# FM33L0XX register map
File version: 1.0
CPU: SC000 r1p0, little endian, no MPU, no FPU, 3 interrupt priority bits
Registers are 32-bit, read-write, reset 0x0 unless marked. A register's access mark holds for its fields unless they carry their own. Offsets are from the block's base; [hi:lo] are bit positions.

## U7816 — U7816 Registers
Base 0x40011C00
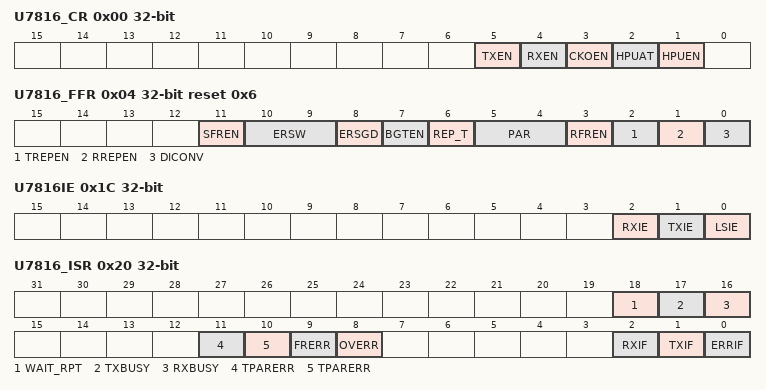
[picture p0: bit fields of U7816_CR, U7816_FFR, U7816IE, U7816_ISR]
0x00 U7816_CR — U7816 CONTROL REGISTER
  [5] TXEN — TX ENABLE
    0=TX_DIS (TX DISABLE); 1=TX_EN (TX ENABLE)
  [4] RXEN — RX ENABLE
    0=RX_DIS (RX DISABLE); 1=RX_EN (RX ENABLE)
  [3] CKOEN — CLK OUTPUT ENABLE
    0=CKO_DIS (CLK OUPUT DISABLE); 1=CKO_EN (CLK OUTPUT ENABLE)
  [2] HPUAT — AUTO PULLUP ENABLE
    0=DISABLE (AUTO PULLUP DISABLE); 1=ENABLE (AUTO PULLUP ENABLE)
  [1] HPUEN — PULLUP ENABLE
    0=DISABLE (PULLUP DISABLE); 1=ENABLE (PULLUP ENABLE)
0x04 U7816_FFR reset 0x6 — U7816 FRAME CONTROL
  [11] SFREN
    0=2 etu; 1=3 etu
  [10:9] ERSW — ERROR SIGNAL LENGTH
    0=2ETU; 1=2ETU; 2=1.5ETU; 3=1ETU
  [8] ERSGD — GUARDTIME LENGTH AFTER ERROR SIGNAL
    0=2.5ETU (2~2.5ETU); 1=1.5ETU (1~1.5ETU)
  [7] BGTEN — block guard time enable
    0=BGT_DIS (BGT DISABLE); 1=BGT_EN
  [6] REP_T — REPEAT TIME
    0=1T; 1=3T
  [5:4] PAR — PARITY MODE
    0=Even; 1=Odd; 2=Always1; 3=NOT_HANDLE
  [3] RFREN — Guard Time Length
    0=2ETU; 1=1ETU
  [2] TREPEN — AUTO POSTBACK WHEN RECEIVED ERROR SIGNAL
  [1] RREPEN — AUTO POSTBACK ERROR SIGNAL WHEN PARITY_ERR
  [0] DICONV — DIRECTION CONV
    0=LSB (LSB FIRST); 1=MSB (MSB FIRST)
0x08 U7816EGT — U7816 EGT config
  [7:0] TXEGT
0x0C U7816CLKDIV reset 0x3 — U7816 CLK DIVIDED CONFIG
  [4:0] CLKDIV — CLK DIVIDED F7816=FAPBCLK/(CLKDIV+1)
0x10 U7816_BGR reset 0x173 — U7816 FREQ DIVISION CONFIG
  [11:0] PDIV — Baud = F7816/(PDIV+1)
0x14 U7816_RXBUF
  [7:0] RXBUF
0x18 U7816_TXBUF
  [7:0] TXBUF
0x1C U7816IE
  [2] RXIE
  [1] TXIE
  [0] LSIE — FOR ERROR_FLAG
0x20 U7816_ISR — U7816 IF
  [18] WAIT_RPT
  [17] TXBUSY
  [16] RXBUSY
  [11] TPARERR — TX PARITY ERROR
  [10] TPARERR — TX PARITY ERROR
  [9] FRERR — FRAME ERROR
  [8] OVERR — OVerflow ERROR
  [2] RXIF
  [1] TXIF
  [0] ERRIF

## UART_COMMON — UART_COMMON Registers
Base 0x40012008
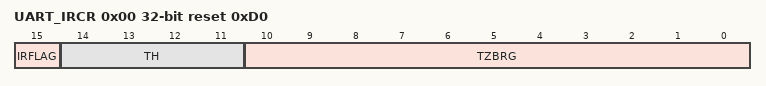
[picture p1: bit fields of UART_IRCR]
0x00 UART_IRCR reset 0xD0 — IR CONFIG
  [15] IRFLAG
  [14:11] TH — duty cuycle Y = (TZBRG[10:4] * TH) /(TZBRG+1)
  [10:0] TZBRG — FIR = Fpclk / (TZBRG +1)

## UART0 — UART0 Registers
Base 0x4001200C
Same registers: UART1 0x4001202C, UART4 0x4001208C, UART5 0x400120AC
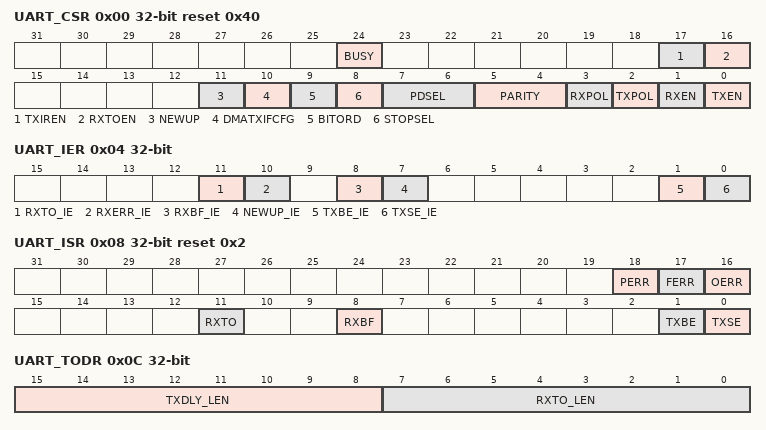
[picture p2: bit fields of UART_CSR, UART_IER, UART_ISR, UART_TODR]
0x00 UART_CSR reset 0x40 — UART Config
  [24] BUSY ro — UARTx BUSY
    0=NO BUSY; 1=BUSY
  [17] TXIREN — UARTx TXIREN
    0=DISABLE; 1=ENABLE
  [16] RXTOEN — UARTx RXTOEN
    0=DISABLE; 1=ENABLE
  [11] NEWUP — UARTx Negedge Wakeup
    0=DISABLE; 1=ENABLE
  [10] DMATXIFCFG — UARTx DMATXIFCFG
    0=DEPENDS; 1=ENABLE
  [9] BITORD — UARTx BITORD
    0=1BIT (1 STOPBIT); 1=2BIT (2 STOPBIT)
  [8] STOPSEL — STOP BIT select
    0=1BIT (1 STOPBIT); 1=2BIT (2 STOPBIT)
  [7:6] PDSEL — UARTx PDSEL
    0=7 BIT (UARx 7 BIT); 1=8 BIT (UARx 8 BIT); 2=9 BIT (UARx 9 BIT)
  [5:4] PARITY — UARTx PARITY
    0=NO PARITY (UARx NO PARITY BIT); 1=PARITY EVEN (UARx PARITY EVEN); 2=PARITY ODD (UARx PARITY ODD)
  [3] RXPOL — UARTx RXPOL
    0=NORMAL (UARx RX NORMAL); 1=REVERSE (UARx RX REVERSE)
  [2] TXPOL — UARTx TXPOL
    0=NORMAL (UARx TX NORMAL); 1=REVERSE (UARx TX REVERSE)
  [1] RXEN — RX ENABLE
  [0] TXEN — TX ENable
0x04 UART_IER — UART IE Config
  [all] fields
    0=DISABLE; 1=ENABLE
  [11] RXTO_IE — UARTx RXTO_IE
  [10] RXERR_IE — UARTx RXERR_IE
  [8] RXBF_IE — UART RXBF_IE
  [7] NEWUP_IE — UARTx NEWUP_IE
  [1] TXBE_IE — UARTx TXBE_IE
  [0] TXSE_IE — UARTx TXSE_IE
0x08 UART_ISR reset 0x2 — UARTxIF Status
  [all] fields
    0=DISABLE; 1=ENABLE
  [18] PERR — UARTx PERR_IF
  [17] FERR — UARTx FERR_IF
  [16] OERR — UARTx OERR_IF
  [11] RXTO — UARTx RXTO_IF
  [8] RXBF — UARTx RXBF_IF
  [1] TXBE — UARTx TXBE
  [0] TXSE — UART TXSE_IF
0x0C UART_TODR — UART RTXDLY
  [15:8] TXDLY_LEN — UARTx TXDLY
  [7:0] RXTO_LEN — UARTx RXDLY
0x10 UART_RXBUF
  [8:0] RXBUF ro — UARTx RXBUF
0x14 UART_TXBUF
  [8:0] TXBUF
0x18 UARTx_BRG reset 0x341 — baudrate setting register
  [15:0] SPBRG — Baud = FAPBCLK / (SPBRG+1)
